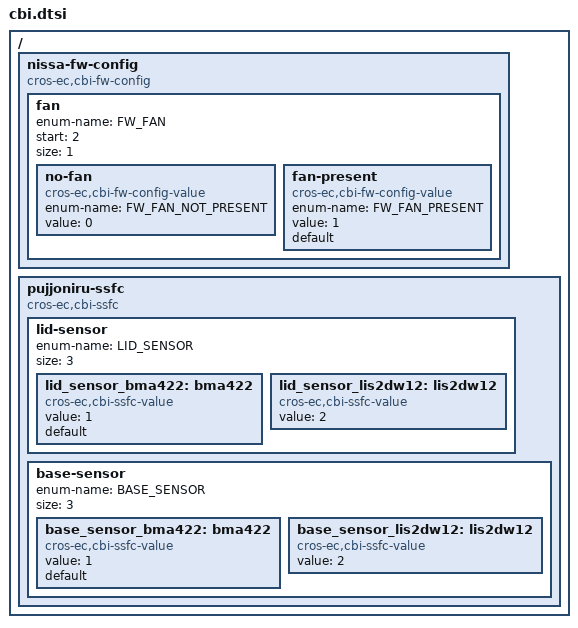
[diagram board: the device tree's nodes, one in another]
/* Copyright 2025 The ChromiumOS Authors
 * Use of this source code is governed by a BSD-style license that can be
 * found in the LICENSE file.
 */

/ {
    /* PUJJONIRU-specific fw_config fields. */
	nissa-fw-config {
        compatible = "cros-ec,cbi-fw-config";
        /*
        * FW_CONFIG field to enable fan or not.
        */
        fan {
            enum-name = "FW_FAN";
            start = <2>;
            size = <1>;

            no-fan {
                compatible = "cros-ec,cbi-fw-config-value";
                enum-name = "FW_FAN_NOT_PRESENT";
                value = <0>;
            };
            fan-present {
                compatible = "cros-ec,cbi-fw-config-value";
                enum-name = "FW_FAN_PRESENT";
                value = <1>;
                /*
                    * Set as default so that unprovisioned
                    * configs will run the fan regardless.
                    */
                default;
            };
        };
    };

    pujjoniru-ssfc {
		compatible = "cros-ec,cbi-ssfc";

		/* SSFC field to identify lid motion sensor. */
		lid-sensor {
			enum-name = "LID_SENSOR";
			size = <3>;

			lid_sensor_bma422: bma422 {
				compatible = "cros-ec,cbi-ssfc-value";
				status = "okay";
				value = <1>;
				default;
			};
			lid_sensor_lis2dw12: lis2dw12 {
				compatible = "cros-ec,cbi-ssfc-value";
				status = "okay";
				value = <2>;
			};
		};

		/* SSFC field to identify base motion sensor. */
		base-sensor {
			enum-name = "BASE_SENSOR";
			size = <3>;

			base_sensor_bma422: bma422 {
				compatible = "cros-ec,cbi-ssfc-value";
				status = "okay";
				value = <1>;
				default;
			};
			base_sensor_lis2dw12: lis2dw12 {
				compatible = "cros-ec,cbi-ssfc-value";
				status = "okay";
				value = <2>;
			};
		};
	};
};
